# K32W061 register map
Vendor: nxp.com; File version: 1.0
CPU: CM4 r0p1, little endian, MPU, no FPU, VTOR, 3 interrupt priority bits
Registers are 32-bit, read-write, reset 0x0 unless marked. A register's access mark holds for its fields unless they carry their own. Offsets are from the block's base; [hi:lo] are bit positions; {n}, {i} and the like mark numbered series.

## FLASH — This is the description of component input mux. . More details will follow.
Base 0x40009000
0x00 CMD wo — command register
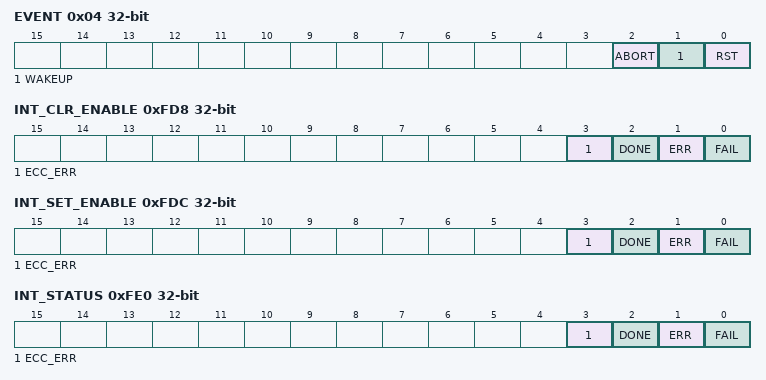
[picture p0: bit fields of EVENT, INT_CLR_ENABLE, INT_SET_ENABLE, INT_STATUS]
0x04 EVENT reset not defined
  [2] ABORT wo — When bit is set, a running program/erase command is aborted.
  [1] WAKEUP wo — When bit is set, the controller wakes up from whatever low power or powerdown mode was active. If not in a powerdown mode, this bit has no effect.
  [0] RST wo — When bit is set, the controller and flash are reset.
0x0C AUTOPROG — specifies what commands are performed on AHB write
  [1:0] AUTOPROG — Auto programmings configuration. 00: auto programming switched off. 01: execute write word . 10: execute write word then, if the last word in a page was written, program page . 11: reserved for future use / no action.
0x10 STARTA — start address for next flash command
  [17:0] STARTA — Address / Start address for commands that take an address (range) as a parameter. The address is in units of memory words, not bytes.
0x14 STOPA — end address for next flash command, if command operates on address ranges
  [17:0] STOPA — Stop address for commands that take an address range as a parameter (the word specified by STOPA is included in the address range). The address is in units of memory words, not bytes.
{0x80+4i} DATAW[{i}] (i=0..3) — data register, word 0-3; Memory data, or command parameter, or command result.
  [31:0] DATAW
0xFD8 INT_CLR_ENABLE reset not defined — Clear interrupt enable bits
  [3] ECC_ERR wo — When a CLR_ENABLE bit is written to 1, the corresponding INT_ENABLE bit is cleared
  [2] DONE wo — When a CLR_ENABLE bit is written to 1, the corresponding INT_ENABLE bit is cleared
  [1] ERR wo — When a CLR_ENABLE bit is written to 1, the corresponding INT_ENABLE bit is cleared
  [0] FAIL wo — When a CLR_ENABLE bit is written to 1, the corresponding INT_ENABLE bit is cleared
0xFDC INT_SET_ENABLE reset not defined — Set interrupt enable bits
  [3] ECC_ERR wo — When a SET_ENABLE bit is written to 1, the corresponding INT_ENABLE bit is set
  [2] DONE wo — When a SET_ENABLE bit is written to 1, the corresponding INT_ENABLE bit is set
  [1] ERR wo — When a SET_ENABLE bit is written to 1, the corresponding INT_ENABLE bit is set
  [0] FAIL wo — When a SET_ENABLE bit is written to 1, the corresponding INT_ENABLE bit is set
0xFE0 INT_STATUS ro — Interrupt status bits
  [3] ECC_ERR — This status bit is set if, during a memory read operation (either a user-requested read, or a speculative read, or reads performed by a controller command), a correctable or uncorrectable error is detected by ECC decoding logic.
  [2] DONE — This status bit is set at the end of command execution
  [1] ERR — This status bit is set if execution of an illegal command is detected. A command is illegal if it is unknown, or it is not allowed in the current mode, or it is violating access restrictions, or it has invalid parameters.
  [0] FAIL — This status bit is set if execution of a (legal) command failed. The flag can be set at any time during command execution, not just at the end.
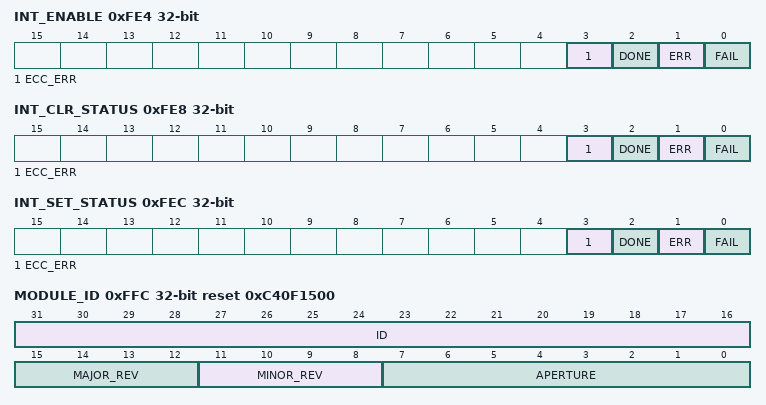
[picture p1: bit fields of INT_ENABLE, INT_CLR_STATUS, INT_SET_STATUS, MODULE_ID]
0xFE4 INT_ENABLE ro — Interrupt enable bits
  [3] ECC_ERR — If an INT_ENABLE bit is set, an interrupt request will be generated if the corresponding INT_STATUS bit is high.
  [2] DONE — If an INT_ENABLE bit is set, an interrupt request will be generated if the corresponding INT_STATUS bit is high.
  [1] ERR — If an INT_ENABLE bit is set, an interrupt request will be generated if the corresponding INT_STATUS bit is high.
  [0] FAIL — If an INT_ENABLE bit is set, an interrupt request will be generated if the corresponding INT_STATUS bit is high.
0xFE8 INT_CLR_STATUS reset not defined — Clear interrupt status bits
  [3] ECC_ERR wo — When a CLR_STATUS bit is written to 1, the corresponding INT_STATUS bit is cleared
  [2] DONE wo — When a CLR_STATUS bit is written to 1, the corresponding INT_STATUS bit is cleared
  [1] ERR wo — When a CLR_STATUS bit is written to 1, the corresponding INT_STATUS bit is cleared
  [0] FAIL wo — When a CLR_STATUS bit is written to 1, the corresponding INT_STATUS bit is cleared
0xFEC INT_SET_STATUS reset not defined — Set interrupt status bits
  [3] ECC_ERR wo — When a SET_STATUS bit is written to 1, the corresponding INT_STATUS bit is set
  [2] DONE wo — When a SET_STATUS bit is written to 1, the corresponding INT_STATUS bit is set
  [1] ERR wo — When a SET_STATUS bit is written to 1, the corresponding INT_STATUS bit is set
  [0] FAIL wo — When a SET_STATUS bit is written to 1, the corresponding INT_STATUS bit is set
0xFFC MODULE_ID ro reset 0xC40F1500 — Controller and Memory module identification
  [31:16] ID — Identifier. This is the unique identifier of the module
  [15:12] MAJOR_REV — Major revision i.e. implies software modifications
  [11:8] MINOR_REV — Minor revision i.e. with no software consequences
  [7:0] APERTURE — Aperture i.e. number minus 1 of consecutive packets 4 Kbytes reserved for this IP
